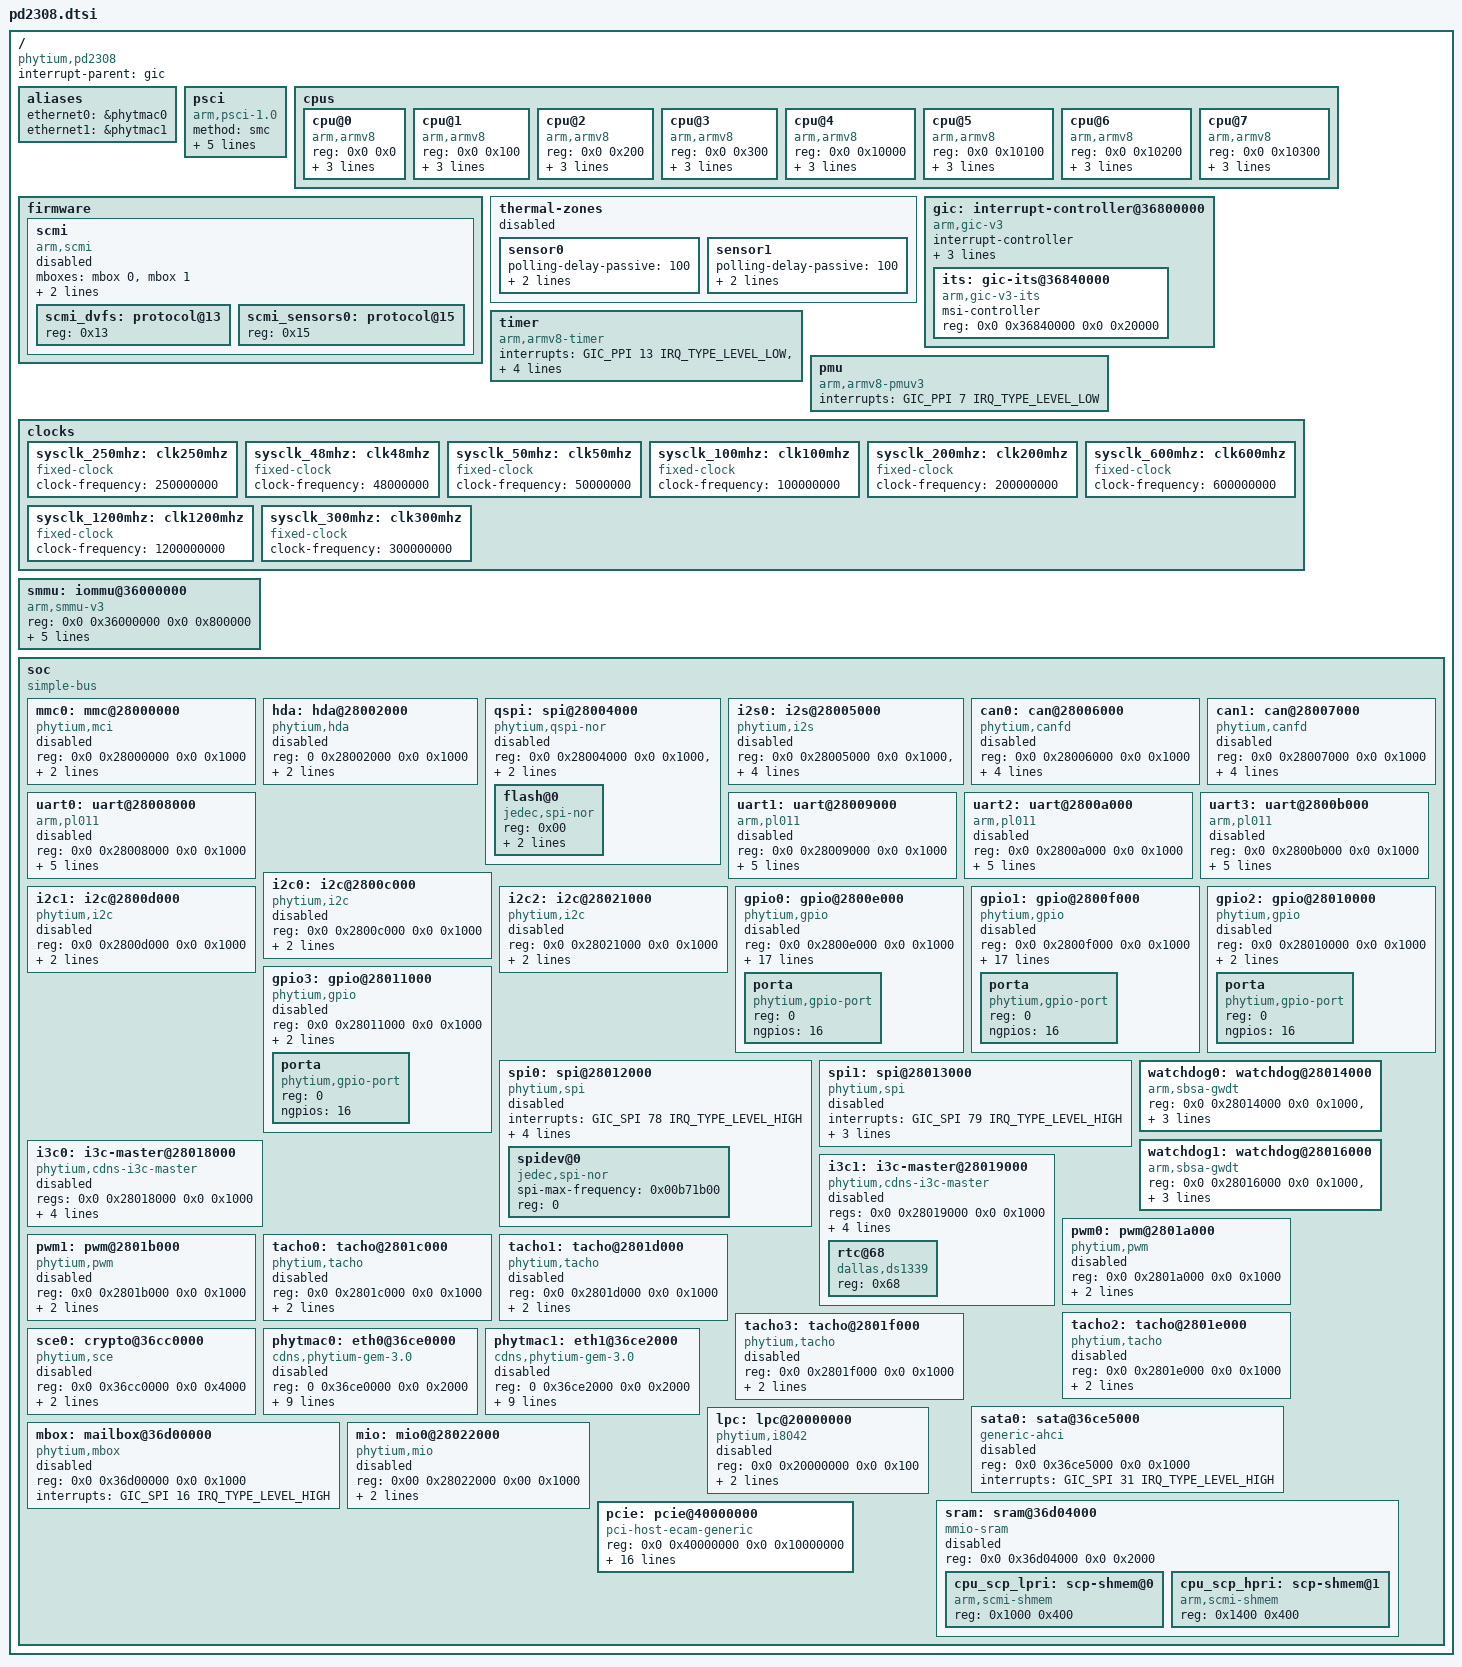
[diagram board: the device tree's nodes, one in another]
// SPDX-License-Identifier: GPL-2.0
/*
 * dts file for Phytium pd308 SoC
 *
 * Copyright (C) 2023, Phytium Technology Co., Ltd.
 */

#include <dt-bindings/interrupt-controller/arm-gic.h>

/ {
	compatible = "phytium,pd2308";
	interrupt-parent = <&gic>;
	#address-cells = <2>;
	#size-cells = <2>;

	aliases {
		ethernet0 = &phytmac0;
		ethernet1 = &phytmac1;
	};

	psci {
		compatible   = "arm,psci-1.0", "arm,psci-0.2", "arm,psci";
		method       = "smc";
		cpu_suspend  = <0xc4000001>;
		cpu_off      = <0x84000002>;
		cpu_on       = <0xc4000003>;
		sys_poweroff = <0x84000008>;
		sys_reset    = <0x84000009>;
	};

	cpus {
		#address-cells = <0x2>;
		#size-cells = <0x0>;
		cpu@0 {
			device_type = "cpu";
			compatible = "arm,armv8";
			reg = <0x0 0x0>;
			enable-method = "psci";
			clocks = <&scmi_dvfs 0>;
			numa-node-id = <0x00000000>;
		};
		cpu@1 {
			device_type = "cpu";
			compatible = "arm,armv8";
			reg = <0x0 0x100>;
			enable-method = "psci";
			clocks = <&scmi_dvfs 1>;
			numa-node-id = <0x0>;
		};
		cpu@2 {
			device_type = "cpu";
			compatible = "arm,armv8";
			reg = <0x0 0x200>;
			enable-method = "psci";
			clocks = <&scmi_dvfs 2>;
			numa-node-id = <0x0>;
		};
		cpu@3 {
			device_type = "cpu";
			compatible = "arm,armv8";
			reg = <0x0 0x300>;
			enable-method = "psci";
			clocks = <&scmi_dvfs 3>;
			numa-node-id = <0x0>;
		};
		cpu@4 {
			device_type = "cpu";
			compatible = "arm,armv8";
			reg = <0x0 0x10000>;
			enable-method = "psci";
			clocks = <&scmi_dvfs 4>;
			numa-node-id = <0x0>;
		};
		cpu@5 {
			device_type = "cpu";
			compatible = "arm,armv8";
			reg = <0x0 0x10100>;
			enable-method = "psci";
			clocks = <&scmi_dvfs 5>;
			numa-node-id = <0x0>;
		};
		cpu@6 {
			device_type = "cpu";
			compatible = "arm,armv8";
			reg = <0x0 0x10200>;
			enable-method = "psci";
			clocks = <&scmi_dvfs 6>;
			numa-node-id = <0x0>;
		};
		cpu@7 {
			device_type = "cpu";
			compatible = "arm,armv8";
			reg = <0x0 0x10300>;
			enable-method = "psci";
			clocks = <&scmi_dvfs 7>;
			numa-node-id = <0x0>;
		};
	};

	firmware {
		scmi: scmi {
			compatible = "arm,scmi";
			mboxes = <&mbox 0 &mbox 1>;
			mbox-names = "tx", "rx";
			shmem = <&cpu_scp_hpri &cpu_scp_lpri>;
			#address-cells = <1>;
			#size-cells = <0>;
			status = "disabled";

			scmi_dvfs: protocol@13 {
				reg = <0x13>;
				#clock-cells = <1>;
			};

			scmi_sensors0: protocol@15 {
				reg = <0x15>;
				#thermal-sensor-cells = <1>;
			};
		};
	};

	thermal-zones {
		status = "disabled";
		sensor0 {
			polling-delay-passive = <100>;
			polling-delay = <1000>;
			thermal-sensors = <&scmi_sensors0 0>;
		};

		sensor1 {
			polling-delay-passive = <100>;
			polling-delay = <1000>;
			thermal-sensors = <&scmi_sensors0 1>;
		};
	};

	gic: interrupt-controller@36800000 {
		compatible = "arm,gic-v3";
		#interrupt-cells = <3>;
		#address-cells = <2>;
		#size-cells = <2>;
		ranges;
		interrupt-controller;
		reg = <0x0 0x36800000 0 0x20000>,       /* GICD */
		      <0x0 0x36860000 0 0x100000>;      /* GICR */

		interrupts = <GIC_PPI 9 IRQ_TYPE_LEVEL_HIGH>;
		phandle = <0x1>;

		its: gic-its@36840000 {
			compatible = "arm,gic-v3-its";
			msi-controller;
			reg = <0x0 0x36840000 0x0 0x20000>;
			phandle = <0x3>;
		};
	};

	timer {
		compatible = "arm,armv8-timer";
		interrupts = <GIC_PPI 13 IRQ_TYPE_LEVEL_LOW>,
			     <GIC_PPI 14 IRQ_TYPE_LEVEL_LOW>,
			     <GIC_PPI 11 IRQ_TYPE_LEVEL_LOW>,
			     <GIC_PPI 10 IRQ_TYPE_LEVEL_LOW>;
		clock-frequency = <50000000>;
	};

	pmu {
		compatible = "arm,armv8-pmuv3";
		interrupts = <GIC_PPI 7 IRQ_TYPE_LEVEL_LOW>;
	};

	clocks {
		#address-cells = <2>;
		#size-cells = <2>;
		ranges;

		sysclk_250mhz: clk250mhz {
			compatible = "fixed-clock";
			#clock-cells = <0>;
			clock-frequency = <250000000>;
		};

		sysclk_48mhz: clk48mhz {
			compatible = "fixed-clock";
			#clock-cells = <0>;
			clock-frequency = <48000000>;
		};

		sysclk_50mhz: clk50mhz {
			compatible = "fixed-clock";
			#clock-cells = <0>;
			clock-frequency = <50000000>;
		};

		sysclk_100mhz: clk100mhz {
			compatible = "fixed-clock";
			#clock-cells = <0>;
			clock-frequency = <100000000>;
		};

		sysclk_200mhz: clk200mhz {
			compatible = "fixed-clock";
			#clock-cells = <0>;
			clock-frequency = <200000000>;
		};

		sysclk_600mhz: clk600mhz {
			compatible = "fixed-clock";
			#clock-cells = <0>;
			clock-frequency = <600000000>;
		};

		sysclk_1200mhz: clk1200mhz {
			compatible = "fixed-clock";
			#clock-cells = <0>;
			clock-frequency = <1200000000>;
		};

		sysclk_300mhz: clk300mhz {
			compatible = "fixed-clock";
			#clock-cells = <0>;
			clock-frequency = <300000000>;
		};
	};

	smmu: iommu@36000000 {
		compatible = "arm,smmu-v3";
		reg = <0x0 0x36000000 0x0 0x800000>;
		interrupts = <GIC_SPI 47 IRQ_TYPE_EDGE_RISING>,
			     <GIC_SPI 46 IRQ_TYPE_EDGE_RISING>,
			     <GIC_SPI 44 IRQ_TYPE_EDGE_RISING>,
			     <GIC_SPI 49 IRQ_TYPE_EDGE_RISING>;
		interrupt-names = "eventq", "priq", "cmdq-sync", "gerror";
		dma-coherent;
		#iommu-cells = <1>;
	};

	soc {
		compatible = "simple-bus";
		#address-cells = <2>;
		#size-cells = <2>;
		ranges;

		mmc0: mmc@28000000 {
			compatible = "phytium,mci";
			reg = <0x0 0x28000000 0x0 0x1000>;
			interrupts = <GIC_SPI 64 IRQ_TYPE_LEVEL_HIGH>;
			clocks = <&sysclk_1200mhz>;
			clock-names = "phytium_mci_clk";
			status = "disabled";
		};

		hda: hda@28002000 {
			compatible = "phytium,hda";
			reg = <0 0x28002000 0x0 0x1000>;
			interrupts = <GIC_SPI 66 IRQ_TYPE_LEVEL_HIGH>;
			clocks = <&sysclk_48mhz>;
			clock-names = "phytium_hda_clk";
			status = "disabled";
		};

		qspi: spi@28004000 {
			compatible = "phytium,qspi-nor";
			reg = <0x0 0x28004000 0x0 0x1000>,
			      <0x0 0x00 0x0 0x10000000>;
			reg-names = "qspi", "qspi_mm";
			clocks = <&sysclk_50mhz>;
			status = "disabled";
			#address-cells = <1>;
			#size-cells = <0>;
			flash@0 {
				compatible = "jedec,spi-nor";
				reg = <0x00>;
				spi-rx-bus-width = <1>;
				spi-max-frequency = <5000000>;
			};
		};

		i2s0: i2s@28005000 {
			compatible = "phytium,i2s";
			reg = <0x0 0x28005000 0x0 0x1000>,
				  <0x0 0x28001000 0x0 0x1000>;
			interrupts = <GIC_SPI 65 IRQ_TYPE_LEVEL_HIGH>;
			clocks = <&sysclk_1200mhz>;
			clock-names = "i2s_clk";
			dai-name = "phytium-i2s-lsd";
			status = "disabled";
		};

		can0: can@28006000 {
			compatible = "phytium,canfd";
			reg = <0x0 0x28006000 0x0 0x1000>;
			interrupts = <GIC_SPI 69 IRQ_TYPE_LEVEL_HIGH>;
			clocks = <&sysclk_300mhz>;
			clock-names = "can_clk";
			tx-fifo-depth = <64>;
			rx-fifo-depth = <64>;
			status = "disabled";
		};

		can1: can@28007000 {
			compatible = "phytium,canfd";
			reg = <0x0 0x28007000 0x0 0x1000>;
			interrupts = <GIC_SPI 70 IRQ_TYPE_LEVEL_HIGH>;
			clocks = <&sysclk_300mhz>;
			clock-names = "can_clk";
			tx-fifo-depth = <64>;
			rx-fifo-depth = <64>;
			status = "disabled";
		};

		uart0: uart@28008000 {
			compatible = "arm,pl011", "arm,primecell";
			reg = <0x0 0x28008000 0x0 0x1000>;
			baud = <115200>;
			reg-shift = <2>;
			reg-io-width = <4>;
			interrupts = <GIC_SPI 71 IRQ_TYPE_LEVEL_HIGH>;
			clocks = <&sysclk_100mhz &sysclk_100mhz>;
			clock-names = "uartclk", "apb_pclk";
			status = "disabled";
		};

		uart1: uart@28009000 {
			compatible = "arm,pl011", "arm,primecell";
			reg = <0x0 0x28009000 0x0 0x1000>;
			baud = <115200>;
			reg-shift = <2>;
			reg-io-width = <4>;
			interrupts = <GIC_SPI 72 IRQ_TYPE_LEVEL_HIGH>;
			clocks = <&sysclk_100mhz &sysclk_100mhz>;
			clock-names = "uartclk", "apb_pclk";
			status = "disabled";
		};

		uart2: uart@2800a000 {
			compatible = "arm,pl011", "arm,primecell";
			reg = <0x0 0x2800a000 0x0 0x1000>;
			baud = <115200>;
			reg-shift = <2>;
			reg-io-width = <4>;
			interrupts = <GIC_SPI 73 IRQ_TYPE_LEVEL_HIGH>;
			clocks = <&sysclk_100mhz &sysclk_100mhz>;
			clock-names = "uartclk", "apb_pclk";
			status = "disabled";
		};

		uart3: uart@2800b000 {
			compatible = "arm,pl011", "arm,primecell";
			reg = <0x0 0x2800b000 0x0 0x1000>;
			baud = <115200>;
			reg-shift = <2>;
			reg-io-width = <4>;
			interrupts = <GIC_SPI 74 IRQ_TYPE_LEVEL_HIGH>;
			clocks = <&sysclk_100mhz &sysclk_100mhz>;
			clock-names = "uartclk", "apb_pclk";
			status = "disabled";
		};

		i2c0: i2c@2800c000 {
			compatible = "phytium,i2c";
			reg = <0x0 0x2800c000 0x0 0x1000>;
			interrupts = <GIC_SPI 76 IRQ_TYPE_LEVEL_HIGH>;
			clocks = <&sysclk_50mhz>;
			status = "disabled";
		};

		i2c1: i2c@2800d000 {
			compatible = "phytium,i2c";
			reg = <0x0 0x2800d000 0x0 0x1000>;
			interrupts = <GIC_SPI 77 IRQ_TYPE_LEVEL_HIGH>;
			clocks = <&sysclk_50mhz>;
			status = "disabled";
		};

		i2c2: i2c@28021000 {
			compatible = "phytium,i2c";
			reg = <0x0 0x28021000 0x0 0x1000>;
			interrupts = <GIC_SPI 92 IRQ_TYPE_LEVEL_HIGH>;
			clocks = <&sysclk_50mhz>;
			status = "disabled";
		};

		gpio0: gpio@2800e000 {
			compatible = "phytium,gpio";
			reg = <0x0 0x2800e000 0x0 0x1000>;
			interrupts = <GIC_SPI 96 IRQ_TYPE_LEVEL_HIGH>,
				     <GIC_SPI 97 IRQ_TYPE_LEVEL_HIGH>,
				     <GIC_SPI 98 IRQ_TYPE_LEVEL_HIGH>,
				     <GIC_SPI 99 IRQ_TYPE_LEVEL_HIGH>,
				     <GIC_SPI 100 IRQ_TYPE_LEVEL_HIGH>,
				     <GIC_SPI 101 IRQ_TYPE_LEVEL_HIGH>,
				     <GIC_SPI 102 IRQ_TYPE_LEVEL_HIGH>,
				     <GIC_SPI 103 IRQ_TYPE_LEVEL_HIGH>,
				     <GIC_SPI 104 IRQ_TYPE_LEVEL_HIGH>,
				     <GIC_SPI 105 IRQ_TYPE_LEVEL_HIGH>,
				     <GIC_SPI 106 IRQ_TYPE_LEVEL_HIGH>,
				     <GIC_SPI 107 IRQ_TYPE_LEVEL_HIGH>,
				     <GIC_SPI 108 IRQ_TYPE_LEVEL_HIGH>,
				     <GIC_SPI 109 IRQ_TYPE_LEVEL_HIGH>,
				     <GIC_SPI 110 IRQ_TYPE_LEVEL_HIGH>,
				     <GIC_SPI 111 IRQ_TYPE_LEVEL_HIGH>;
			gpio-controller;
			#gpio-cells = <2>;
			#address-cells = <1>;
			#size-cells = <0>;
			status = "disabled";

			porta {
				compatible = "phytium,gpio-port";
				reg = <0>;
				ngpios = <16>;
			};
		};

		gpio1: gpio@2800f000 {
			compatible = "phytium,gpio";
			reg = <0x0 0x2800f000 0x0 0x1000>;
			interrupts = <GIC_SPI 112 IRQ_TYPE_LEVEL_HIGH>,
				     <GIC_SPI 113 IRQ_TYPE_LEVEL_HIGH>,
				     <GIC_SPI 114 IRQ_TYPE_LEVEL_HIGH>,
				     <GIC_SPI 115 IRQ_TYPE_LEVEL_HIGH>,
				     <GIC_SPI 116 IRQ_TYPE_LEVEL_HIGH>,
				     <GIC_SPI 117 IRQ_TYPE_LEVEL_HIGH>,
				     <GIC_SPI 118 IRQ_TYPE_LEVEL_HIGH>,
				     <GIC_SPI 119 IRQ_TYPE_LEVEL_HIGH>,
				     <GIC_SPI 120 IRQ_TYPE_LEVEL_HIGH>,
				     <GIC_SPI 121 IRQ_TYPE_LEVEL_HIGH>,
				     <GIC_SPI 122 IRQ_TYPE_LEVEL_HIGH>,
				     <GIC_SPI 123 IRQ_TYPE_LEVEL_HIGH>,
				     <GIC_SPI 124 IRQ_TYPE_LEVEL_HIGH>,
				     <GIC_SPI 125 IRQ_TYPE_LEVEL_HIGH>,
				     <GIC_SPI 126 IRQ_TYPE_LEVEL_HIGH>,
				     <GIC_SPI 127 IRQ_TYPE_LEVEL_HIGH>;
			gpio-controller;
			#gpio-cells = <2>;
			#address-cells = <1>;
			#size-cells = <0>;
			status = "disabled";

			porta {
				compatible = "phytium,gpio-port";
				reg = <0>;
				ngpios = <16>;
			};
		};

		gpio2: gpio@28010000 {
			compatible = "phytium,gpio";
			reg = <0x0 0x28010000 0x0 0x1000>;
			interrupts = <GIC_SPI 128 IRQ_TYPE_LEVEL_HIGH>;
			gpio-controller;
			#gpio-cells = <2>;
			#address-cells = <1>;
			#size-cells = <0>;
			status = "disabled";

			porta {
				compatible = "phytium,gpio-port";
				reg = <0>;
				ngpios = <16>;
			};
		};

		gpio3: gpio@28011000 {
			compatible = "phytium,gpio";
			reg = <0x0 0x28011000 0x0 0x1000>;
			interrupts = <GIC_SPI 129 IRQ_TYPE_LEVEL_HIGH>;
			gpio-controller;
			#gpio-cells = <2>;
			#address-cells = <1>;
			#size-cells = <0>;
			status = "disabled";

			porta {
				compatible = "phytium,gpio-port";
				reg = <0>;
				ngpios = <16>;
			};
		};

		spi0: spi@28012000 {
			compatible = "phytium,spi";
			interrupts = <GIC_SPI 78 IRQ_TYPE_LEVEL_HIGH>;
			reg = <0x0 0x28012000 0x0 0x1000>;
			clocks = <&sysclk_50mhz>;
			num-cs = <4>;
			status = "disabled";
			#address-cells = <1>;
			#size-cells = <0>;
			global-cs = <1>;

			spidev@0 {
				compatible = "jedec,spi-nor";
				spi-max-frequency = <0x00b71b00>;
				reg = <0>;
			};
		};

		spi1: spi@28013000 {
			compatible = "phytium,spi";
			interrupts = <GIC_SPI 79 IRQ_TYPE_LEVEL_HIGH>;
			reg = <0x0 0x28013000 0x0 0x1000>;
			clocks = <&sysclk_50mhz>;
			num-cs = <4>;
			status = "disabled";
		};

		watchdog0: watchdog@28014000 {
			compatible = "arm,sbsa-gwdt";
			reg = <0x0 0x28014000 0x0 0x1000>,
			     <0x0 0x28015000 0x0 0x1000>;
			interrupts = <GIC_SPI 80 IRQ_TYPE_LEVEL_HIGH>;
			timeout-sec = <30>;
		};

		watchdog1: watchdog@28016000 {
			compatible = "arm,sbsa-gwdt";
			reg = <0x0 0x28016000 0x0 0x1000>,
			     <0x0 0x28017000 0x0 0x1000>;
			interrupts = <GIC_SPI 81 IRQ_TYPE_LEVEL_HIGH>;
			timeout-sec = <30>;
		};

		i3c0: i3c-master@28018000 {
			compatible = "phytium,cdns-i3c-master";
			regs = <0x0 0x28018000 0x0 0x1000>;
			interrupts = <GIC_SPI 82 IRQ_TYPE_LEVEL_HIGH>;
			clocks = <&sysclk_50mhz>, <&sysclk_50mhz>;
			clock-names = "pclk", "sysclk";
			#address-cells = <1>;
			#size-cells = <0>;
			i2c-scl-hz = <400000>;
			i3c-scl-hz = <1000000>;
			status = "disabled";
		};

		i3c1: i3c-master@28019000 {
			compatible = "phytium,cdns-i3c-master";
			regs = <0x0 0x28019000 0x0 0x1000>;
			interrupts = <GIC_SPI 83 IRQ_TYPE_LEVEL_HIGH>;
			clocks = <&sysclk_50mhz>, <&sysclk_50mhz>;
			clock-names = "pclk", "sysclk";
			#address-cells = <1>;
			#size-cells = <0>;
			i2c-scl-hz = <400000>;
			i3c-scl-hz = <1000000>;
			status = "disabled";
			rtc@68 {
				compatible = "dallas,ds1339";
				reg = <0x68>;
			};
		};

		pwm0: pwm@2801a000 {
			compatible = "phytium,pwm";
			reg = <0x0 0x2801a000 0x0 0x1000>;
			interrupts = <GIC_SPI 86 IRQ_TYPE_LEVEL_HIGH>;
			clocks = <&sysclk_50mhz>;
			status = "disabled";
		};

		pwm1: pwm@2801b000 {
			compatible = "phytium,pwm";
			reg = <0x0 0x2801b000 0x0 0x1000>;
			interrupts = <GIC_SPI 87 IRQ_TYPE_LEVEL_HIGH>;
			clocks = <&sysclk_50mhz>;
			status = "disabled";
		};

		tacho0: tacho@2801c000 {
			compatible = "phytium,tacho";
			reg = <0x0 0x2801c000 0x0 0x1000>;
			interrupts = <GIC_SPI 88 IRQ_TYPE_LEVEL_HIGH>;
			clocks = <&sysclk_50mhz>;
			status = "disabled";
		};

		tacho1: tacho@2801d000 {
			compatible = "phytium,tacho";
			reg = <0x0 0x2801d000 0x0 0x1000>;
			interrupts = <GIC_SPI 89 IRQ_TYPE_LEVEL_HIGH>;
			clocks = <&sysclk_50mhz>;
			status = "disabled";
		};

		tacho2: tacho@2801e000 {
			compatible = "phytium,tacho";
			reg = <0x0 0x2801e000 0x0 0x1000>;
			interrupts = <GIC_SPI 90 IRQ_TYPE_LEVEL_HIGH>;
			clocks = <&sysclk_50mhz>;
			status = "disabled";
		};

		tacho3: tacho@2801f000 {
			compatible = "phytium,tacho";
			reg = <0x0 0x2801f000 0x0 0x1000>;
			interrupts = <GIC_SPI 91 IRQ_TYPE_LEVEL_HIGH>;
			clocks = <&sysclk_50mhz>;
			status = "disabled";
		};

		sce0: crypto@36cc0000 {
			compatible = "phytium,sce";
			reg = <0x0 0x36cc0000 0x0 0x4000>;
			interrupts = <GIC_SPI 19 IRQ_TYPE_LEVEL_HIGH>;
			host-number = <2>;
			status = "disabled";
		};

		phytmac0: eth0@36ce0000 {
			compatible = "cdns,phytium-gem-3.0";
			reg = <0 0x36ce0000 0x0 0x2000>;
			interrupts = <GIC_SPI 32 IRQ_TYPE_LEVEL_HIGH>,
				     <GIC_SPI 33 IRQ_TYPE_LEVEL_HIGH>,
				     <GIC_SPI 34 IRQ_TYPE_LEVEL_HIGH>,
				     <GIC_SPI 35 IRQ_TYPE_LEVEL_HIGH>;
			clock-names = "pclk", "hclk", "tx_clk", "rx_clk","tsu_clk";
			clocks = <&sysclk_250mhz>, <&sysclk_250mhz>,<&sysclk_250mhz>,
				 <&sysclk_250mhz>,<&sysclk_300mhz>;
			magic-packet;
			dma-coherent;
			queue-number = <0x04>;
			status = "disabled";
		};


		phytmac1: eth1@36ce2000 {
			compatible = "cdns,phytium-gem-3.0";
			reg = <0 0x36ce2000 0x0 0x2000>;
			interrupts = <GIC_SPI 36 IRQ_TYPE_LEVEL_HIGH>,
				     <GIC_SPI 37 IRQ_TYPE_LEVEL_HIGH>,
				     <GIC_SPI 38 IRQ_TYPE_LEVEL_HIGH>,
				     <GIC_SPI 39 IRQ_TYPE_LEVEL_HIGH>;
			clock-names = "pclk", "hclk", "tx_clk", "rx_clk","tsu_clk";
			clocks = <&sysclk_250mhz>, <&sysclk_250mhz>,<&sysclk_250mhz>,
				 <&sysclk_250mhz>,<&sysclk_300mhz>;
			magic-packet;
			dma-coherent;
			queue-number = <0x04>;
			status = "disabled";
		};

		sata0: sata@36ce5000 {
			compatible = "generic-ahci";
			reg = <0x0 0x36ce5000 0x0 0x1000>;
			interrupts = <GIC_SPI 31 IRQ_TYPE_LEVEL_HIGH>;
			status = "disabled";
		};

		lpc: lpc@20000000 {
			compatible = "phytium,i8042";
			#address-cells = <2>;
			#size-cells = <2>;
			reg = <0x0 0x20000000 0x0 0x100>;
			interrupts = <GIC_SPI 85 IRQ_TYPE_LEVEL_HIGH>;
			lpc_version = <1>;
			status = "disabled";
		};

		mbox: mailbox@36d00000 {
			compatible = "phytium,mbox";
			reg = <0x0 0x36d00000 0x0 0x1000>;
			interrupts = <GIC_SPI 16 IRQ_TYPE_LEVEL_HIGH>;
			#mbox-cells = <1>;
			status = "disabled";
		};

		sram: sram@36d04000 {
			compatible = "mmio-sram";
			reg = <0x0 0x36d04000 0x0 0x2000>;

			#address-cells = <1>;
			#size-cells = <1>;
			ranges = <0x0 0x0 0x36d04000 0x2000>;
			status = "disabled";

			cpu_scp_lpri: scp-shmem@0 {
				compatible = "arm,scmi-shmem";
				reg = <0x1000 0x400>;
			};

			cpu_scp_hpri: scp-shmem@1 {
				compatible = "arm,scmi-shmem";
				reg = <0x1400 0x400>;
			};
		};

		mio: mio0@28022000 {
			compatible = "phytium,mio";
			reg = <0x00 0x28022000 0x00 0x1000>;
			interrupts = <0 93 4>;
			clocks = <&sysclk_50mhz &sysclk_50mhz>;
			clock-names = "mio_clk";
			status = "disabled";
		};

		pcie: pcie@40000000 {
			compatible = "pci-host-ecam-generic";
			device_type = "pci";
			#address-cells = <3>;
			#size-cells = <2>;
			#interrupt-cells = <1>;
			reg = <0x0 0x40000000 0x0 0x10000000>;
			msi-parent = <&its>;
			bus-range = <0x0 0xff>;
			interrupt-map-mask = <0x0 0x0 0x0 0x7>;
			interrupt-map = <0x0 0x0 0x0 0x1 &gic
				     0x0 0x0 GIC_SPI 4 IRQ_TYPE_LEVEL_HIGH>,
				     <0x0 0x0 0x0 0x2 &gic
				     0x0 0x0 GIC_SPI 5 IRQ_TYPE_LEVEL_HIGH>,
				     <0x0 0x0 0x0 0x3 &gic
				     0x0 0x0 GIC_SPI 6 IRQ_TYPE_LEVEL_HIGH>,
				     <0x0 0x0 0x0 0x4 &gic
				     0x0 0x0 GIC_SPI 7 IRQ_TYPE_LEVEL_HIGH>;
			ranges = <0x1000000 0x00 0x00 0x0  0x50000000  0x0  0xf00000>,
				     <0x2000000 0x00 0x58000000 0x0  0x58000000  0x0  0x28000000>,
				     <0x3000000 0x10 0x00000000 0x10 0x00000000  0x10 0x00000000>;
			dma-ranges = <0x43000000 0x00 0x00 0x00 0x00 0x1000 0x00>;
			iommu-map = <0x0 &smmu 0x0 0x10000>;
			io-upper = <0x50005000>;
			dma-coherent;
		};
	};
};
